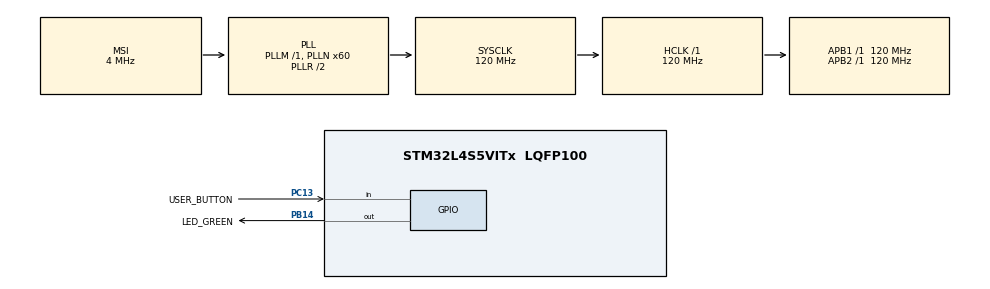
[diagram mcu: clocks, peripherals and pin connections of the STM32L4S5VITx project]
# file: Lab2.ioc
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ADC1.Channel-3\#ChannelRegularConversion=ADC_CHANNEL_TEMPSENSOR
ADC1.NbrOfConversionFlag=1
ADC1.OffsetNumber-3\#ChannelRegularConversion=ADC_OFFSET_NONE
ADC1.Rank-3\#ChannelRegularConversion=1
ADC1.SamplingTime-3\#ChannelRegularConversion=ADC_SAMPLETIME_640CYCLES_5
ADC1.master=1
Mcu.Family=STM32L4
Mcu.Name=STM32L4S5VITx
Mcu.Package=LQFP100
NVIC.PriorityGroup=NVIC_PRIORITYGROUP_4
PB14.GPIO_Label=LED_GREEN
PB14.Signal=GPIO_Output
PC13.GPIO_Label=USER_BUTTON
PC13.Signal=GPIO_Input
ProjectManager.HeapSize=0x200
ProjectManager.StackSize=0x400
ProjectManager.TargetToolchain=STM32CubeIDE
RCC.ADCFreq_Value=80000000
RCC.AHBFreq_Value=120000000
RCC.APB1Freq_Value=120000000
RCC.APB1TimFreq_Value=120000000
RCC.APB2Freq_Value=120000000
RCC.APB2TimFreq_Value=120000000
RCC.CortexFreq_Value=120000000
RCC.HCLKFreq_Value=120000000
RCC.HSE_VALUE=8000000
RCC.HSI48_VALUE=48000000
RCC.HSI_VALUE=16000000
RCC.LSE_VALUE=32768
RCC.MSI_VALUE=4000000
RCC.PLLN=60
RCC.PLLSAI1N=40
RCC.SYSCLKFreq_VALUE=120000000
RCC.SYSCLKSource=RCC_SYSCLKSOURCE_PLLCLK
RCC.USBFreq_Value=80000000
RCC.VCOOutputFreq_Value=240000000
VP_ADC1_TempSens_Input.Mode=IN-TempSens
VP_ADC1_Vref_Input.Mode=IN-Vrefint
board=B-L4S5I-IOT01A

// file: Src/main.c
/* USER CODE BEGIN Header */
/**
  ******************************************************************************
  * @file           : main.c
  * @brief          : Main program body
  ******************************************************************************
  * @attention
  *
  * <h2><center>&copy; Copyright (c) 2021 STMicroelectronics.
  * All rights reserved.</center></h2>
  *
  * This software component is licensed by ST under BSD 3-Clause license,
  * the "License"; You may not use this file except in compliance with the
  * License. You may obtain a copy of the License at:
  *                        opensource.org/licenses/BSD-3-Clause
  *
  ******************************************************************************
  */
/* USER CODE END Header */
#include "main.h"

ADC_HandleTypeDef hadc1;

void SystemClock_Config(void);
static void MX_GPIO_Init(void);
static void MX_ADC1_Init(void);

/* USER CODE BEGIN 0 */
void ChangeADCChannel(ADC_HandleTypeDef *hadc1, int LEDState) {
	ADC_ChannelConfTypeDef sConfig = {0};
	if (LEDState == 0) {	// When LED is off, Channel is VREFINT
		sConfig.Channel = ADC_CHANNEL_VREFINT;
		sConfig.Rank = ADC_REGULAR_RANK_1;
		sConfig.SamplingTime = ADC_SAMPLETIME_640CYCLES_5;
		sConfig.SingleDiff = ADC_SINGLE_ENDED;
		sConfig.OffsetNumber = ADC_OFFSET_NONE;
		sConfig.Offset = 0;
		if (HAL_ADC_ConfigChannel(hadc1, &sConfig) != HAL_OK)
		{
		    Error_Handler();
		}
	}

	else {		// When LED is on, Channel is TEMPSENSOR
		sConfig.Channel = ADC_CHANNEL_TEMPSENSOR;
		sConfig.Rank = ADC_REGULAR_RANK_1;
		sConfig.SamplingTime = ADC_SAMPLETIME_640CYCLES_5;
		sConfig.SingleDiff = ADC_SINGLE_ENDED;
		sConfig.OffsetNumber = ADC_OFFSET_NONE;
		sConfig.Offset = 0;
		if (HAL_ADC_ConfigChannel(hadc1, &sConfig) != HAL_OK)
		{
		    Error_Handler();
		}
	}
}
/* USER CODE END 0 */

int main(void)
{

  /* MCU Configuration--------------------------------------------------------*/

  /* Reset of all peripherals, Initializes the Flash interface and the Systick. */
  HAL_Init();

  /* Configure the system clock */
  SystemClock_Config();

  /* Initialize all configured peripherals */
  MX_GPIO_Init();
  MX_ADC1_Init();
  /* USER CODE BEGIN 2 */
  int previousButtonState = GPIO_PIN_SET;
  int previousLEDState = GPIO_PIN_SET;
  HAL_GPIO_WritePin(GPIOB, GPIO_PIN_14, GPIO_PIN_SET);

  uint16_t VREFINT_DATA = 0;
  float Vref = 0;
  uint16_t TS_DATA = 0;
  float Temp = 0;

  float part1 = 0;
  float part2 = 0;
  float part3 = 0;

  HAL_ADCEx_Calibration_Start(&hadc1, ADC_SINGLE_ENDED);
  /* USER CODE END 2 */

  /* Infinite loop */
  while (1)
  {

    /* USER CODE BEGIN 3 */
	  // Press button once and stays at this state until the button is pressed the second time
	  // Default LED state should be 1, because of pull-up resistor
	  // When the button is depressed the logic state is LOW, otherwise, the logic state is HIGH

	  int currentButtonState = HAL_GPIO_ReadPin(GPIOC, GPIO_PIN_13);
	  if (currentButtonState != previousButtonState) {
		  if (currentButtonState == GPIO_PIN_RESET) {
			  HAL_GPIO_TogglePin(GPIOB, GPIO_PIN_14);
		  }
		  previousButtonState = currentButtonState;
	  }

	  // When LED is on, read temperature, when LED is off, read voltage
	  int currentLEDState = HAL_GPIO_ReadPin(GPIOB, GPIO_PIN_14);
	  if (currentLEDState == previousLEDState);
	  else {
		  ChangeADCChannel(&hadc1, currentLEDState);
	  }
	  if (currentLEDState == GPIO_PIN_SET) {
		  HAL_ADC_Start(&hadc1);
		  if (HAL_ADC_PollForConversion(&hadc1, 1000) == HAL_OK) {
			  TS_DATA = HAL_ADC_GetValue(&hadc1);
			  part1 = (float)TEMPSENSOR_CAL2_TEMP - (float)TEMPSENSOR_CAL1_TEMP;
			  part2 = (float)*TEMPSENSOR_CAL2_ADDR - (float)*TEMPSENSOR_CAL1_ADDR;
			  part3 = (float)TS_DATA * 3.3 / 3 - (float)*TEMPSENSOR_CAL1_ADDR;
			  Temp = part1 / part2 * part3 + 30;
		  }
	  }
	  else {
		  HAL_ADC_Start(&hadc1);
		  if (HAL_ADC_PollForConversion(&hadc1, 1000) == HAL_OK) {
			  VREFINT_DATA = HAL_ADC_GetValue(&hadc1);
			  // VDDA = VREF+ = 3.0V
			  // VREFINT_CAL_ADDR: address of parameter VREFINT_CAL
			  Vref = 3.0 * ((float)*VREFINT_CAL_ADDR / (float)VREFINT_DATA);
		  }
	  }
	  previousLEDState = currentLEDState;
  }
  /* USER CODE END 3 */
}

void SystemClock_Config(void)
{
  RCC_OscInitTypeDef RCC_OscInitStruct = {0};
  RCC_ClkInitTypeDef RCC_ClkInitStruct = {0};
  RCC_PeriphCLKInitTypeDef PeriphClkInit = {0};

  /** Configure the main internal regulator output voltage
  */
  if (HAL_PWREx_ControlVoltageScaling(PWR_REGULATOR_VOLTAGE_SCALE1_BOOST) != HAL_OK)
  {
    Error_Handler();
  }
  /** Initializes the RCC Oscillators according to the specified parameters
  * in the RCC_OscInitTypeDef structure.
  */
  RCC_OscInitStruct.OscillatorType = RCC_OSCILLATORTYPE_MSI;
  RCC_OscInitStruct.MSIState = RCC_MSI_ON;
  RCC_OscInitStruct.MSICalibrationValue = 0;
  RCC_OscInitStruct.MSIClockRange = RCC_MSIRANGE_6;
  RCC_OscInitStruct.PLL.PLLState = RCC_PLL_ON;
  RCC_OscInitStruct.PLL.PLLSource = RCC_PLLSOURCE_MSI;
  RCC_OscInitStruct.PLL.PLLM = 1;
  RCC_OscInitStruct.PLL.PLLN = 60;
  RCC_OscInitStruct.PLL.PLLP = RCC_PLLP_DIV2;
  RCC_OscInitStruct.PLL.PLLQ = RCC_PLLQ_DIV2;
  RCC_OscInitStruct.PLL.PLLR = RCC_PLLR_DIV2;
  if (HAL_RCC_OscConfig(&RCC_OscInitStruct) != HAL_OK)
  {
    Error_Handler();
  }
  /** Initializes the CPU, AHB and APB buses clocks
  */
  RCC_ClkInitStruct.ClockType = RCC_CLOCKTYPE_HCLK|RCC_CLOCKTYPE_SYSCLK
                              |RCC_CLOCKTYPE_PCLK1|RCC_CLOCKTYPE_PCLK2;
  RCC_ClkInitStruct.SYSCLKSource = RCC_SYSCLKSOURCE_PLLCLK;
  RCC_ClkInitStruct.AHBCLKDivider = RCC_SYSCLK_DIV1;
  RCC_ClkInitStruct.APB1CLKDivider = RCC_HCLK_DIV1;
  RCC_ClkInitStruct.APB2CLKDivider = RCC_HCLK_DIV1;

  if (HAL_RCC_ClockConfig(&RCC_ClkInitStruct, FLASH_LATENCY_5) != HAL_OK)
  {
    Error_Handler();
  }
  PeriphClkInit.PeriphClockSelection = RCC_PERIPHCLK_ADC;
  PeriphClkInit.AdcClockSelection = RCC_ADCCLKSOURCE_PLLSAI1;
  PeriphClkInit.PLLSAI1.PLLSAI1Source = RCC_PLLSOURCE_MSI;
  PeriphClkInit.PLLSAI1.PLLSAI1M = 1;
  PeriphClkInit.PLLSAI1.PLLSAI1N = 40;
  PeriphClkInit.PLLSAI1.PLLSAI1P = RCC_PLLP_DIV2;
  PeriphClkInit.PLLSAI1.PLLSAI1Q = RCC_PLLQ_DIV2;
  PeriphClkInit.PLLSAI1.PLLSAI1R = RCC_PLLR_DIV2;
  PeriphClkInit.PLLSAI1.PLLSAI1ClockOut = RCC_PLLSAI1_ADC1CLK;
  if (HAL_RCCEx_PeriphCLKConfig(&PeriphClkInit) != HAL_OK)
  {
    Error_Handler();
  }
}

static void MX_ADC1_Init(void)
{

  ADC_ChannelConfTypeDef sConfig = {0};

  /** Common config
  */
  hadc1.Instance = ADC1;
  hadc1.Init.ClockPrescaler = ADC_CLOCK_ASYNC_DIV1;
  hadc1.Init.Resolution = ADC_RESOLUTION_12B;
  hadc1.Init.DataAlign = ADC_DATAALIGN_RIGHT;
  hadc1.Init.ScanConvMode = ADC_SCAN_DISABLE;
  hadc1.Init.EOCSelection = ADC_EOC_SINGLE_CONV;
  hadc1.Init.LowPowerAutoWait = DISABLE;
  hadc1.Init.ContinuousConvMode = DISABLE;
  hadc1.Init.NbrOfConversion = 1;
  hadc1.Init.DiscontinuousConvMode = DISABLE;
  hadc1.Init.ExternalTrigConv = ADC_SOFTWARE_START;
  hadc1.Init.ExternalTrigConvEdge = ADC_EXTERNALTRIGCONVEDGE_NONE;
  hadc1.Init.DMAContinuousRequests = DISABLE;
  hadc1.Init.Overrun = ADC_OVR_DATA_PRESERVED;
  hadc1.Init.OversamplingMode = DISABLE;
  if (HAL_ADC_Init(&hadc1) != HAL_OK)
  {
    Error_Handler();
  }
  /** Configure Regular Channel
  */
  sConfig.Channel = ADC_CHANNEL_TEMPSENSOR;
  sConfig.Rank = ADC_REGULAR_RANK_1;
  sConfig.SamplingTime = ADC_SAMPLETIME_640CYCLES_5;
  sConfig.SingleDiff = ADC_SINGLE_ENDED;
  sConfig.OffsetNumber = ADC_OFFSET_NONE;
  sConfig.Offset = 0;
  if (HAL_ADC_ConfigChannel(&hadc1, &sConfig) != HAL_OK)
  {
    Error_Handler();
  }

}

static void MX_GPIO_Init(void)
{
  GPIO_InitTypeDef GPIO_InitStruct = {0};

  /* GPIO Ports Clock Enable */
  __HAL_RCC_GPIOC_CLK_ENABLE();
  __HAL_RCC_GPIOB_CLK_ENABLE();

  /*Configure GPIO pin Output Level */
  HAL_GPIO_WritePin(LED_GREEN_GPIO_Port, LED_GREEN_Pin, GPIO_PIN_RESET);

  /*Configure GPIO pin : USER_BUTTON_Pin */
  GPIO_InitStruct.Pin = USER_BUTTON_Pin;
  GPIO_InitStruct.Mode = GPIO_MODE_INPUT;
  GPIO_InitStruct.Pull = GPIO_NOPULL;
  HAL_GPIO_Init(USER_BUTTON_GPIO_Port, &GPIO_InitStruct);

  /*Configure GPIO pin : LED_GREEN_Pin */
  GPIO_InitStruct.Pin = LED_GREEN_Pin;
  GPIO_InitStruct.Mode = GPIO_MODE_OUTPUT_PP;
  GPIO_InitStruct.Pull = GPIO_NOPULL;
  GPIO_InitStruct.Speed = GPIO_SPEED_FREQ_LOW;
  HAL_GPIO_Init(LED_GREEN_GPIO_Port, &GPIO_InitStruct);

}

void Error_Handler(void)
{
  __disable_irq();
  while (1)
  {
  }
}

/************************ (C) COPYRIGHT STMicroelectronics *****END OF FILE****/
